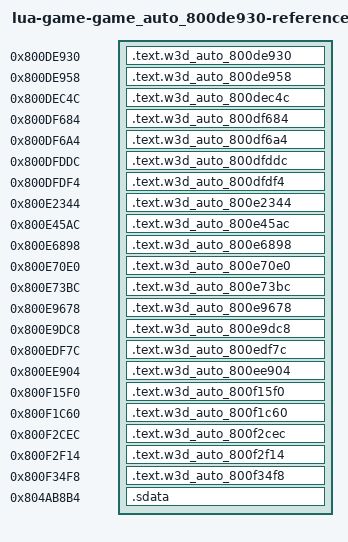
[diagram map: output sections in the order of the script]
/* Generated reference-only placements. All bodies are source-built. */
OUTPUT_FORMAT("elf32-powerpc")
OUTPUT_ARCH(powerpc)
ENTRY(w3d_auto_800de930)
_SDA_BASE_ = 0x804b2540;
_SDA2_BASE_ = 0x804c2540;
fn_800DC6FC = 0x800dc6fc;
fn_800DD334 = 0x800dd334;
fn_800DFA00 = 0x800dfa00;
fn_800E0400 = 0x800e0400;
fn_800E68F0 = 0x800e68f0;
fn_800E73F0 = 0x800e73f0;
fn_800E7450 = 0x800e7450;
fn_800ECF4C = 0x800ecf4c;
fn_800FC1B0 = 0x800fc1b0;
fn_800FC6DC = 0x800fc6dc;
fn_80122AF8 = 0x80122af8;
fn_80162BA8 = 0x80162ba8;
fn_80162C18 = 0x80162c18;
fn_80164FC8 = 0x80164fc8;
fn_80178C48 = 0x80178c48;
fn_801797B4 = 0x801797b4;
fn_802098D8 = 0x802098d8;
fn_80209920 = 0x80209920;
fn_80209968 = 0x80209968;
fn_8020BD38 = 0x8020bd38;
fn_802EEFE0 = 0x802eefe0;
fn_80341584 = 0x80341584;
fn_803426B4 = 0x803426b4;
SECTIONS {
  .text.w3d_auto_800de930 0x800de930 : { *(.text.w3d_auto_800de930) }
  .text.w3d_auto_800de958 0x800de958 : { *(.text.w3d_auto_800de958) }
  .text.w3d_auto_800dec4c 0x800dec4c : { *(.text.w3d_auto_800dec4c) }
  .text.w3d_auto_800df684 0x800df684 : { *(.text.w3d_auto_800df684) }
  .text.w3d_auto_800df6a4 0x800df6a4 : { *(.text.w3d_auto_800df6a4) }
  .text.w3d_auto_800dfddc 0x800dfddc : { *(.text.w3d_auto_800dfddc) }
  .text.w3d_auto_800dfdf4 0x800dfdf4 : { *(.text.w3d_auto_800dfdf4) }
  .text.w3d_auto_800e2344 0x800e2344 : { *(.text.w3d_auto_800e2344) }
  .text.w3d_auto_800e45ac 0x800e45ac : { *(.text.w3d_auto_800e45ac) }
  .text.w3d_auto_800e6898 0x800e6898 : { *(.text.w3d_auto_800e6898) }
  .text.w3d_auto_800e70e0 0x800e70e0 : { *(.text.w3d_auto_800e70e0) }
  .text.w3d_auto_800e73bc 0x800e73bc : { *(.text.w3d_auto_800e73bc) }
  .text.w3d_auto_800e9678 0x800e9678 : { *(.text.w3d_auto_800e9678) }
  .text.w3d_auto_800e9dc8 0x800e9dc8 : { *(.text.w3d_auto_800e9dc8) }
  .text.w3d_auto_800edf7c 0x800edf7c : { *(.text.w3d_auto_800edf7c) }
  .text.w3d_auto_800ee904 0x800ee904 : { *(.text.w3d_auto_800ee904) }
  .text.w3d_auto_800f15f0 0x800f15f0 : { *(.text.w3d_auto_800f15f0) }
  .text.w3d_auto_800f1c60 0x800f1c60 : { *(.text.w3d_auto_800f1c60) }
  .text.w3d_auto_800f2cec 0x800f2cec : { *(.text.w3d_auto_800f2cec) }
  .text.w3d_auto_800f2f14 0x800f2f14 : { *(.text.w3d_auto_800f2f14) }
  .text.w3d_auto_800f34f8 0x800f34f8 : { *(.text.w3d_auto_800f34f8) }
  .sdata 0x804ab8b4 (NOLOAD) : {
    . = 0x0; lbl_804AB8B4 = .;
    . += 1; }
  /DISCARD/ : { *(.text*) *(.rodata*) *(.data*) *(.bss*) *(.sdata*) *(.sbss*) *(.comment) }
}
